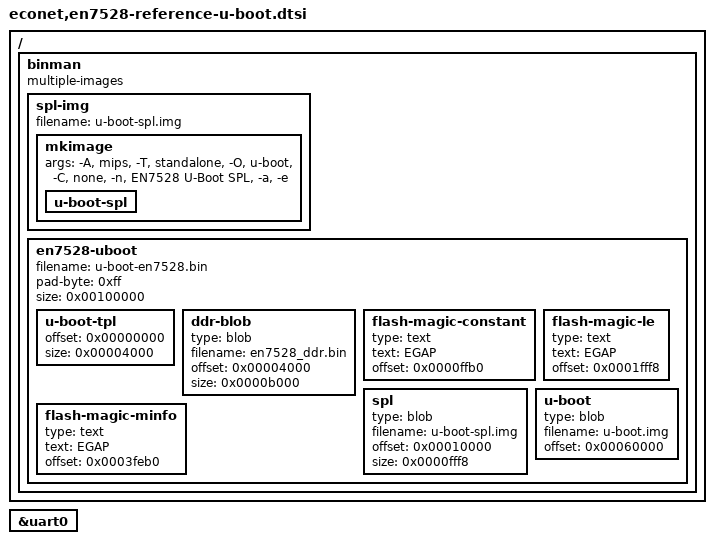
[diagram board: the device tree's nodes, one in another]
// SPDX-License-Identifier: GPL-2.0+
#include <linux/stringify.h>

/ {
	binman: binman {
		multiple-images;
	};
};

&uart0 {
	bootph-all;
};

&binman {
	spl-img {
		filename = "u-boot-spl.img";

		mkimage {
			args = "-A", "mips", "-T", "standalone", "-O", "u-boot",
			       "-C", "none", "-n", "EN7528 U-Boot SPL",
			       "-a", __stringify(CONFIG_SPL_TEXT_BASE),
			       "-e", __stringify(CONFIG_SPL_TEXT_BASE);

			u-boot-spl {
			};
		};
	};

	en7528-uboot {
		filename = "u-boot-en7528.bin";
		pad-byte = <0xff>;
		size = <0x00100000>;

		u-boot-tpl {
			offset = <0x00000000>;
			size = <0x00004000>;
		};

		ddr-blob {
			type = "blob";
			filename = "en7528_ddr.bin";
			offset = <0x00004000>;
			size = <0x0000b000>;
		};

		flash-magic-constant {
			type = "text";
			text = "EGAP";
			offset = <0x0000ffb0>;
		};

		spl {
			type = "blob";
			filename = "u-boot-spl.img";
			offset = <0x00010000>;
			size = <0x0000fff8>;
		};

		/* EN7528 LE internal-ROM NAND ECC boot requires this exact marker. */
		flash-magic-le {
			type = "text";
			text = "EGAP";
			offset = <0x0001fff8>;
		};

		flash-magic-minfo {
			type = "text";
			text = "EGAP";
			offset = <0x0003feb0>;
		};

		u-boot {
			type = "blob";
			filename = "u-boot.img";
			offset = <0x00060000>;
		};
	};
};
